# GD32M53x register map
File version: 1.0
CPU: CM33 r2p1, little endian, MPU, FPU, DSP, 4 interrupt priority bits
Registers are 32-bit, read-write, reset 0x0 unless marked. A register's access mark holds for its fields unless they carry their own. Offsets are from the block's base; [hi:lo] are bit positions; {n}, {i} and the like mark numbered series.

## CRC — cyclic redundancy check calculation unit
Base 0x40023000
0x00 DATA reset 0xFFFFFFFF
  [31:0] DATA — CRC calculation result bits
0x04 FDATA — Free data register
  [7:0] FDATA — Free Data Register bits
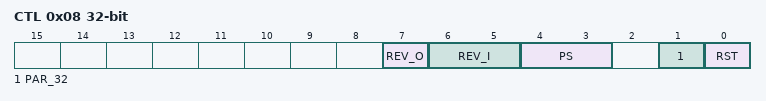
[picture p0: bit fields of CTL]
0x08 CTL — Control register
  [7] REV_O — Reverse output data value in bit order
  [6:5] REV_I — Reverse type for input data
  [4:3] PS — Size of polynomial
  [1] PAR_32 — CRC 32-bit parallel calculation mode
  [0] RST — reset bit
0x10 IDATA reset 0xFFFFFFFF — Initialization data register
  [31:0] IDATA — Configurable initial CRC data value
0x14 POLY reset 0x4C11DB7 — Polynomial register
  [31:0] POLY — User configurable polynomial value

## DAC — Digital-to-analog converter
Base 0x40007400
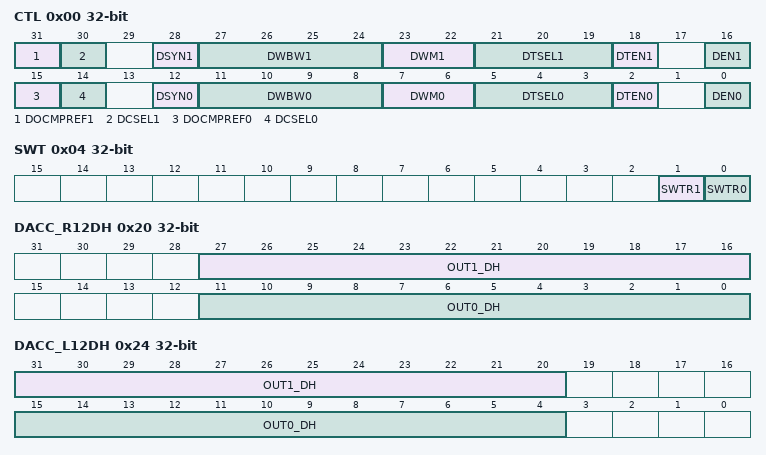
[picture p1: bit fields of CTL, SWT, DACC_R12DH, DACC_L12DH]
0x00 CTL — control register
  [31] DOCMPREF1 — DAC_OUT1 output for CMP reference voltage
  [30] DCSEL1 — DAC_OUT1 connect selection
  [28] DSYN1 — DAC_OUT1 converter operation synchronizes with ADC2 converter operation
  [27:24] DWBW1 — DAC_OUT1 noise wave bit width
  [23:22] DWM1 — DAC_OUT1 noise wave mode
  [21:19] DTSEL1 — DAC_OUT1 trigger selection
  [18] DTEN1 — DAC_OUT1 trigger enable
  [16] DEN1 — DAC_OUT1 enable
  [15] DOCMPREF0 — DAC_OUT0 output for CMP reference voltage
  [14] DCSEL0 — DAC_OUT0 connect selection
  [12] DSYN0 — DAC_OUT0 converter operation synchronizes with ADC2 converter operation
  [11:8] DWBW0 — DAC_OUT0 noise wave bit width
  [7:6] DWM0 — DAC_OUT0 noise wave mode
  [5:3] DTSEL0 — DAC_OUT0 trigger selection
  [2] DTEN0 — DAC_OUT0 trigger enable
  [0] DEN0 — DAC_OUT0 enable
0x04 SWT wo — software trigger register
  [1] SWTR1 — DAC_OUT1 software trigger
  [0] SWTR0 — DAC_OUT0 software trigger
0x08 OUT0_R12DH — DAC_OUT0 12-bit right-aligned data holding register
  [11:0] OUT0_DH — DAC_OUT0 12-bit right-aligned data
0x0C OUT0_L12DH — DAC_OUT0 12-bit left aligned data holding register
  [15:4] OUT0_DH — DAC_OUT0 12-bit left-aligned data
0x14 OUT1_R12DH — DAC_OUT1 12-bit right aligned data holding register
  [11:0] OUT1_DH — DAC_OUT1 12-bit right-aligned data
0x18 OUT1_L12DH — DAC_OUT1 12-bit left aligned data holding register
  [15:4] OUT1_DH — DAC_OUT1 12-bit left-aligned data
0x20 DACC_R12DH — DAC concurrent mode 12-bit right aligned data holding register
  [27:16] OUT1_DH — DAC_OUT1 12-bit right-aligned data
  [11:0] OUT0_DH — DAC_OUT0 12-bit right-aligned data
0x24 DACC_L12DH — DAC concurrent mode 12-bit left aligned data holding register
  [31:20] OUT1_DH — DAC_OUT1 12-bit left-aligned data
  [15:4] OUT0_DH — DAC_OUT0 12-bit left-aligned data
0x2C OUT0_DO ro — DAC_OUT0 data output register
  [11:0] OUT0_DO — DAC_OUT0 12-bit right-aligned data
0x30 OUT1_DO ro — DAC_OUT1 data output register
  [11:0] OUT1_DO — DAC_OUT1 12-bit right-aligned data

## DBG — Debug support
Base 0xE0044000
0x00 ID ro — ID code register
  [31:0] ID_CODE — DBG ID code register
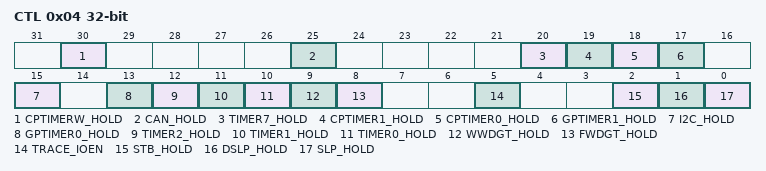
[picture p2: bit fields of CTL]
0x04 CTL — Control register
  [30] CPTIMERW_HOLD — CPTIMERW hold bit
  [25] CAN_HOLD — CAN hold bit
  [20] TIMER7_HOLD — TIMER 7 hold bit
  [19] CPTIMER1_HOLD — CPTIMER1 hold bit
  [18] CPTIMER0_HOLD — CPTIMER0 hold bit
  [17] GPTIMER1_HOLD — GPTIMER1 hold bit
  [15] I2C_HOLD — I2C0 hold bit
  [13] GPTIMER0_HOLD — GPTIMER 0 hold bit
  [12] TIMER2_HOLD — TIMER 2 hold bit
  [11] TIMER1_HOLD — TIMER 1 hold bit
  [10] TIMER0_HOLD — TIMER 0 hold bit
  [9] WWDGT_HOLD — WWDGT hold bit
  [8] FWDGT_HOLD — FWDGT hold bit
  [5] TRACE_IOEN — Trace pin allocation enable
  [2] STB_HOLD — Standby mode hold register
  [1] DSLP_HOLD — Deep-sleep mode hold register
  [0] SLP_HOLD — Sleep mode hold register

## DMA0 — DMA controller
Base 0x40020000
Same registers: DMA1 0x40020400
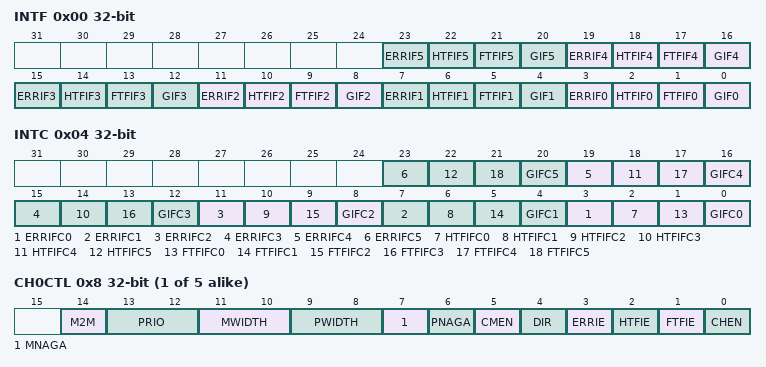
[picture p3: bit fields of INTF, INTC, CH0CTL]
0x00 INTF ro — Interrupt flag register
  [4n+3] ERRIF{n} (n=0..5) — Error flag of channel {n}
  [4n+2] HTFIF{n} (n=0..5) — Half transfer finish flag of channel {n}
  [4n+1] FTFIF{n} (n=0..5) — Full transfer finish flag of channe {n}
  [4n] GIF{n} (n=0..5) — Global interrupt flag of channel {n}
0x04 INTC wo — Interrupt flag clear register
  [4n+3] ERRIFC{n} (n=0..5) — Clear bit for error flag of channel {n}
  [4n+2] HTFIFC{n} (n=0..5) — Clear bit for half transfer finish flag of channel {n}
  [4n+1] FTFIFC{n} (n=0..5) — Clear bit for full transfer finish flag of channel {n}
  [4n] GIFC{n} (n=0..5) — Clear global interrupt flag of channel {n}
{0x8+0x14*i} CH{i}CTL (i=0..4) — Channel {i} control register
  [14] M2M — Memory to memory mode
  [13:12] PRIO — Priority level
  [11:10] MWIDTH — Transfer data size of memory
  [9:8] PWIDTH — Transfer data size of peripheral
  [7] MNAGA — Next address generation algorithm of memory
  [6] PNAGA — Next address generation algorithm of peripheral
  [5] CMEN — Circular mode enable
  [4] DIR — Transfer direction
  [3] ERRIE — Enable bit for channel error interrupt
  [2] HTFIE — Enable bit for channel half transfer finish interrupt
  [1] FTFIE — Enable bit for channel full transfer finish interrupt
  [0] CHEN — Channel enable
{0xC+0x14*i} CH{i}CNT (i=0..4) — Channel {i} counter register
  [15:0] CNT — Transfer counter
{0x10+0x14*i} CH{i}PADDR (i=0..4) — Channel {i} peripheral base address register
  [31:0] PADDR — Peripheral base address
{0x14+0x14*i} CH{i}MADDR (i=0..4) — Channel {i} memory base address register
  [31:0] MADDR — Memory base address
